# NUC1xx_registers register map
File version: 0.1
CPU: 
Registers are 32-bit, read-write, reset 0x0 unless marked. A register's access mark holds for its fields unless they carry their own. Offsets are from the block's base; [hi:lo] are bit positions; lines under a group give offsets from that group; {n}, {i} and the like mark numbered series; 'fields as' and 'values as' point back to an identical list; <NAME> marks a mode.

## PWMA — Registers group
Base 0x40040000
Same registers: PWMB 0x40140000
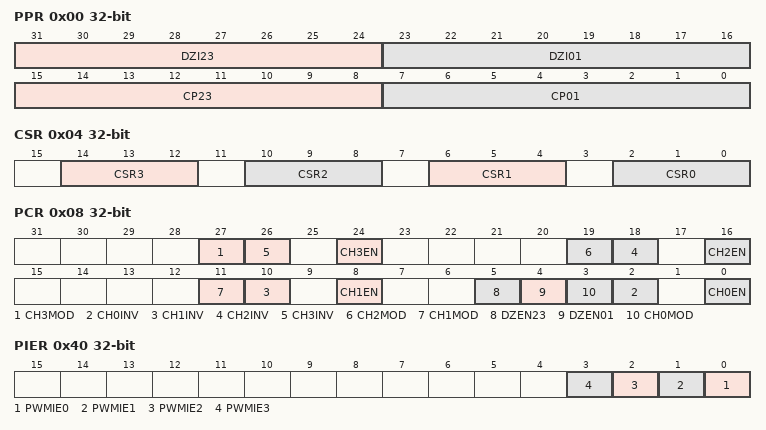
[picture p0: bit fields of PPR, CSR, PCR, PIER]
0x00 PPR — PWM Prescaler Register
  [31:24] DZI23 — Dead Zone Interval for Pair of Channel2 and Channel3 (PWM2 and PWM3 pair for PWM group A, PWM6 and PWM7 pair for PWM group B) These 8 bits determine dead zone length. The unit time of dead zone length is received from corresponding CSR bits.
  [23:16] DZI01 — Dead Zone Interval for Pair of Channel 0 and Channel 1 (PWM0 and PWM1 pair for PWM group A, PWM4 and PWM5 pair for PWM group B) These 8 bits determine dead zone length. The unit time of dead zone length is received from corresponding CSR bits.
  [15:8] CP23 — Clock prescaler 2 (PWM-timer2 & 3 for group A and PWM-timer 6 & 7 for group B) Clock input is divided by (CP23 + 1) before it is fed to the corresponding PWM-timer. If CP23=0, then the clock prescaler 2 output clock will be stopped. So corresponding PWM-timer will be stopped also.
  [7:0] CP01 — Clock prescaler 0 (PWM-timer 0 & 1 for group A and PWM-timer 4 & 5 for group B) Clock input is divided by (CP01 + 1) before it is fed to the corresponding PWM-timer If CP01=0, then the clock prescaler 0 output clock will be stopped. So corresponding PWM-timer will be stopped also.
0x04 CSR — PWM Clock Select Register
  [14:12] CSR3 — PWM Timer 3 Clock Source Selection (PWM timer 3 for group A and PWM timer 7 for group B) Select clock input for PWM timer. CSR3 [14:12] Input clock divided by 100 1 011 16 010 8 001 4 000 2
  [10:8] CSR2 — PWM Timer 2 Clock Source Selection (PWM timer 2 for group A and PWM timer 6 for group B) Select clock input for PWM timer. (Table is the same as CSR3)
  [6:4] CSR1 — PWM Timer 1 Clock Source Selection (PWM timer 1 for group A and PWM timer 5 for group B) Select clock input for PWM timer. (Table is the same as CSR3)
  [2:0] CSR0 — PWM Timer 0 Clock Source Selection (PWM timer 0 for group A and PWM timer 4 for group B) Select clock input for PWM timer. (Table is the same as CSR3)
0x08 PCR — PWM Control Register
  [27] CH3MOD — PWM-Timer 3 Auto-reload/One-Shot Mode (PWM timer 3 for group A and PWM timer 7 for group B) 1 = Auto-reload Mode 0 = One-Shot Mode Note: If there is a rising transition at this bit, it will cause CNR3 and CMR3 be clear.
  [8n+2] CH{n}INV (n=0..3) — PWM-Timer {n} Output Inverter Enable (PWM timer {n} for group A and PWM timer {n+4} for group B) 1 = Inverter enable 0 = Inverter disable
  [8n] CH{n}EN (n=0..3) — PWM-Timer {n} Enable (PWM timer {n} for group A and PWM timer {n+4} for group B) 1 = Enable corresponding PWM-Timer Start Run 0 = Stop corresponding PWM-Timer Running
  [19] CH2MOD — PWM-Timer 2 Auto-reload/One-Shot Mode (PWM timer 2 for group A and PWM timer 6 for group B) 1 = Auto-reload Mode 0 = One-Shot Mode Note: If there is a rising transition at this bit, it will cause CNR2 and CMR2 be clear.
  [11] CH1MOD — PWM-Timer 1 Auto-reload/One-Shot Mode (PWM timer 1 for group A and PWM timer 5 for group B) 1 = Auto-load Mode 0 = One-Shot Mode Note: If there is a rising transition at this bit, it will cause CNR1 and CMR1 be clear.
  [5] DZEN23 — Dead-Zone 2 Generator Enable (PWM2 and PWM3 pair for PWM group A, PWM6 and PWM7 pair for PWM group B) 1 = Enable 0 = Disable Note: When Dead-Zone Generator is enabled, the pair of PWM2 and PWM3 becomes a complementary pair for PWM group A and the pair of PWM6 and PWM7 becomes a complementary pair for PWM group B.
  [4] DZEN01 — Dead-Zone 0 Generator Enable (PWM0 and PWM1 pair for PWM group A, PWM4 and PWM5 pair for PWM group B) 1 = Enable 0 = Disable Note: When Dead-Zone Generator is enabled, the pair of PWM0 and PWM1 becomes a complementary pair for PWM group A and the pair of PWM4 and PWM5 becomes a complementary pair for PWM group B.
  [3] CH0MOD — PWM-Timer 0 Auto-reload/One-Shot Mode (PWM timer 0 for group A and PWM timer 4 for group B) 1 = Auto-reload Mode 0 = One-Shot Mode Note: If there is a rising transition at this bit, it will cause CNR0 and CMR0 be clear.
0x0C CNR0 — PWM Counter Register 0
  [15:0] CNR — PWM Counter/Timer Loaded Value CNR determines the PWM period. PWM frequency = PWM01_CLK/(prescale+1)*(clock divider)/(CNR+1). Duty ratio = (CMR+1)/(CNR+1). CMR >= CNR: PWM output is always high. CMR < CNR: PWM low width = (CNR-CMR) unit; PWM high width = (CMR+1) unit. CMR = 0: PWM low width = (CNR) unit; PWM high width = 1 unit (Unit : 1 PWM clock cycle) Note: Any write to CNR will take effect in next PWM cycle.
0x10 CMR0 — PWM Comparator Register 0
  [15:0] CMR — PWM Comparator Register CMR determines the PWM duty. PWM frequency = PWM01_CLK/(prescale+1)*(clock divider)/(CNR+1). Duty ratio = (CMR+1)/(CNR+1). CMR >= CNR: PWM output is always high. CMR < CNR: PWM low width = (CNR-CMR) unit; PWM high width = (CMR+1) unit. CMR = 0: PWM low width = (CNR) unit; PWM high width = 1 unit (Unit : 1 PWM clock cycle) Note: Any write to CMR will take effect in next PWM cycle.
{0x14+0xC*i} PDR{i} ro (i=0..3) — PWM Data Register {i}
  [15:0] PDR — PWM Data Register User can monitor PDR to know current value in 16-bit down counter.
0x18 CNR1 — PWM Counter Register 1
  fields as CNR0
0x1C CMR1 — PWM Comparator Register 1
  fields as CMR0
0x24 CNR2 — PWM Counter Register 2
  [15:0] CNR — PWM Counter/Timer Loaded Value CNR determines the PWM period. PWM frequency = PWM23_CLK/(prescale+1)*(clock divider)/(CNR+1). Duty ratio = (CMR+1)/(CNR+1). CMR >= CNR: PWM output is always high. CMR < CNR: PWM low width = (CNR-CMR) unit; PWM high width = (CMR+1) unit. CMR = 0: PWM low width = (CNR) unit; PWM high width = 1 unit (Unit : 1 PWM clock cycle) Note: Any write to CNR will take effect in next PWM cycle.
0x28 CMR2 — PWM Comparator Register 2
  [15:0] CMR — PWM Comparator Register CMR determines the PWM duty. PWM frequency = PWM23_CLK/(prescale+1)*(clock divider)/(CNR+1). Duty ratio = (CMR+1)/(CNR+1). CMR >= CNR: PWM output is always high. CMR < CNR: PWM low width = (CNR-CMR) unit; PWM high width = (CMR+1) unit. CMR = 0: PWM low width = (CNR) unit; PWM high width = 1 unit (Unit : 1 PWM clock cycle) Note: Any write to CMR will take effect in next PWM cycle.
0x30 CNR3 — PWM Counter Register 3
  fields as CNR2
0x34 CMR3 — PWM Comparator Register 3
  fields as CMR2
0x3C PBCR — New description for register
  [0] BCn — PWM Backward Compatible Register 0 = PWM register action is compatible with Medium Density 1 = PWM register action is not compatible with Medium Density Please reference CCR0/CCR2 register bit 6, 7, 22, 23 description
0x40 PIER — PWM Interrupt Enable Register
  [n] PWMIE{n} (n=0..3) — PWM Channel {n} Interrupt Enable 1 = Enable 0 = Disable
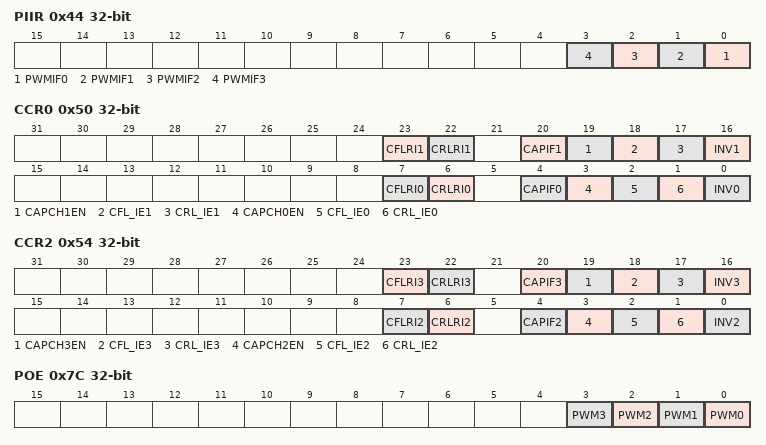
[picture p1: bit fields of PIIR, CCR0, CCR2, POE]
0x44 PIIR — PWM Interrupt Indication Register
  [n] PWMIF{n} write-1-clears (n=0..3) — PWM Channel {n} Interrupt Status Flag is set by hardware when PWM{n} down counter reaches zero, software can write 1 to clear this bit to zero.
0x50 CCR0 — Capture Control Register 0
  [23] CFLRI1 — CFLR1 Latched Indicator Bit When PWM group input channel 1 has a falling transition, CFLR1 was latched with the value of PWM down-counter and this bit is set by hardware. In Medium Density, software can write 0 to clear this bit to zero. In Low Density, software can write 0 to clear this bit to zero if BCn bit is 0, and can Write 1 to clear this bit to zero if BCn bit is 1.
  [22] CRLRI1 — CRLR1 Latched Indicator Bit When PWM group input channel 1 has a rising transition, CRLR1 was latched with the value of PWM down-counter and this bit is set by hardware. In Medium Density, software can write 0 to clear this bit to zero. In Low Density, software can write 0 to clear this bit to zero if BCn bit is 0, and can Write 1 to clear this bit to zero if BCn bit is 1.
  [20] CAPIF1 write-1-clears — Channel 1 Capture Interrupt Indication Flag If PWM group channel 1 rising latch interrupt is enabled (CRL_IE1=1), a rising transition occurs at PWM group channel 1 will result in CAPIF1 to high; Similarly, a falling transition will cause CAPIF1 to be set high if PWM group channel 1 falling latch interrupt is enabled (CFL_IE1=1). Write 1 to clear this bit to zero
  [19] CAPCH1EN — Channel 1 Capture Function Enable 1 = Enable capture function on PWM group channel 1. 0 = Disable capture function on PWM group channel 1. When Enable, Capture latched the PMW-counter and saved to CRLR (Rising latch) and CFLR (Falling latch). When Disable, Capture does not update CRLR and CFLR, and disable PWM group channel 1 Interrupt.
  [18] CFL_IE1 — Channel 1 Falling Latch Interrupt Enable 1 = Enable falling latch interrupt 0 = Disable falling latch interrupt When Enable, if Capture detects PWM group channel 1 has falling transition, Capture issues an Interrupt.
  [17] CRL_IE1 — Channel 1 Rising Latch Interrupt Enable 1 = Enable rising latch interrupt 0 = Disable rising latch interrupt When Enable, if Capture detects PWM group channel 1 has rising transition, Capture issues an Interrupt.
  [16] INV1 — Channel 1 Inverter Enable 1 = Inverter enable. Reverse the input signal from GPIO before fed to Capture timer 0 = Inverter disable
  [7] CFLRI0 — CFLR0 Latched Indicator Bit When PWM group input channel 0 has a falling transition, CFLR0 was latched with the value of PWM down-counter and this bit is set by hardware. In Medium Density, software can write 0 to clear this bit to zero. In Low Density, software can write 0 to clear this bit to zero if BCn bit is 0, and can Write 1 to clear this bit to zero if BCn bit is 1.
  [6] CRLRI0 — CRLR0 Latched Indicator Bit When PWM group input channel 0 has a rising transition, CRLR0 was latched with the value of PWM down-counter and this bit is set by hardware. In Medium Density, software can write 0 to clear this bit to zero. In Low Density, software can write 0 to clear this bit to zero if BCn bit is 0, and can Write 1 to clear this bit to zero if BCn bit is 1.
  [4] CAPIF0 write-1-clears — Channel 0 Capture Interrupt Indication Flag If PWM group channel 0 rising latch interrupt is enabled (CRL_IE0=1), a rising transition occurs at PWM group channel 0 will result in CAPIF0 to high; Similarly, a falling transition will cause CAPIF0 to be set high if PWM group channel 0 falling latch interrupt is enabled (CFL_IE0=1). Write 1 to clear this bit to zero
  [3] CAPCH0EN — Channel 0 Capture Function Enable 1 = Enable capture function on PWM group channel 0. 0 = Disable capture function on PWM group channel 0. When Enable, Capture latched the PWM-counter value and saved to CRLR (Rising latch) and CFLR (Falling latch). When Disable, Capture does not update CRLR and CFLR, and disable PWM group channel 0 Interrupt.
  [2] CFL_IE0 — Channel 0 Falling Latch Interrupt Enable 1 = Enable falling latch interrupt 0 = Disable falling latch interrupt When Enable, if Capture detects PWM group channel 0 has falling transition, Capture issues an Interrupt.
  [1] CRL_IE0 — Channel 0 Rising Latch Interrupt Enable 1 = Enable rising latch interrupt 0 = Disable rising latch interrupt When Enable, if Capture detects PWM group channel 0 has rising transition, Capture issues an Interrupt.
  [0] INV0 — Channel 0 Inverter Enable 1 = Inverter enable. Reverse the input signal from GPIO before fed to Capture timer 0 = Inverter disable
0x54 CCR2 — Capture Control Register 2
  [23] CFLRI3 — CFLR3 Latched Indicator Bit When PWM group input channel 3 has a falling transition, CFLR3 was latched with the value of PWM down-counter and this bit is set by hardware. In Medium Density, software can write 0 to clear this bit to zero. In Low Density, software can write 0 to clear this bit to zero if BCn bit is 0, and can Write 1 to clear this bit to zero if BCn bit is 1.
  [22] CRLRI3 — CRLR3 Latched Indicator Bit When PWM group input channel 3 has a rising transition, CRLR3 was latched with the value of PWM down-counter and this bit is set by hardware. In Medium Density, software can write 0 to clear this bit to zero. In Low Density, software can write 0 to clear this bit to zero if BCn bit is 0, and can Write 1 to clear this bit to zero if BCn bit is 1.
  [20] CAPIF3 write-1-clears — Channel 3 Capture Interrupt Indication Flag If PWM group channel 3 rising latch interrupt is enabled (CRL_IE3=1), a rising transition occurs at PWM group channel 3 will result in CAPIF3 to high; Similarly, a falling transition will cause CAPIF3 to be set high if PWM group channel 3 falling latch interrupt is enabled (CFL_IE3=1). Write 1 to clear this bit to zero
  [19] CAPCH3EN — Channel 3 Capture Function Enable 1 = Enable capture function on PWM group channel 3. 0 = Disable capture function on PWM group channel 3. When Enable, Capture latched the PMW-counter and saved to CRLR (Rising latch) and CFLR (Falling latch). When Disable, Capture does not update CRLR and CFLR, and disable PWM group channel 3 Interrupt.
  [18] CFL_IE3 — Channel 3 Falling Latch Interrupt Enable 1 = Enable falling latch interrupt 0 = Disable falling latch interrupt When Enable, if Capture detects PWM group channel 3 has falling transition, Capture issues an Interrupt.
  [17] CRL_IE3 — Channel 3 Rising Latch Interrupt Enable 1 = Enable rising latch interrupt 0 = Disable rising latch interrupt When Enable, if Capture detects PWM group channel 3 has rising transition, Capture issues an Interrupt.
  [16] INV3 — Channel 3 Inverter Enable 1 = Inverter enable. Reverse the input signal from GPIO before fed to Capture timer 0 = Inverter disable
  [7] CFLRI2 — CFLR2 Latched Indicator Bit When PWM group input channel 2 has a falling transition, CFLR2 was latched with the value of PWM down-counter and this bit is set by hardware. In Medium Density, software can write 0 to clear this bit to zero. In Low Density, software can write 0 to clear this bit to zero if BCn bit is 0, and can Write 1 to clear this bit to zero if BCn bit is 1.
  [6] CRLRI2 — CRLR2 Latched Indicator Bit When PWM group input channel 2 has a rising transition, CRLR2 was latched with the value of PWM down-counter and this bit is set by hardware. In Medium Density, software can write 0 to clear this bit to zero. In Low Density, software can write 0 to clear this bit to zero if BCn bit is 0, and can Write 1 to clear this bit to zero if BCn bit is 1.
  [4] CAPIF2 write-1-clears — Channel 2 Capture Interrupt Indication Flag If PWM group channel 2 rising latch interrupt is enabled (CRL_IE2=1), a rising transition occurs at PWM group channel 2 will result in CAPIF2 to high; Similarly, a falling transition will cause CAPIF2 to be set high if PWM group channel 2 falling latch interrupt is enabled (CFL_IE2=1). Write 1 to clear this bit to zero
  [3] CAPCH2EN — Channel 2 Capture Function Enable 1 = Enable capture function on PWM group channel 2. 0 = Disable capture function on PWM group channel 2. When Enable, Capture latched the PWM-counter value and saved to CRLR (Rising latch) and CFLR (Falling latch). When Disable, Capture does not update CRLR and CFLR, and disable PWM group channel 2 Interrupt.
  [2] CFL_IE2 — Channel 2 Falling Latch Interrupt Enable 1 = Enable falling latch interrupt 0 = Disable falling latch interrupt When Enable, if Capture detects PWM group channel 2 has falling transition, Capture issues an Interrupt.
  [1] CRL_IE2 — Channel 2 Rising Latch Interrupt Enable 1 = Enable rising latch interrupt 0 = Disable rising latch interrupt When Enable, if Capture detects PWM group channel 2 has rising transition, Capture issues an Interrupt.
  [0] INV2 — Channel 2 Inverter Enable 1 = Inverter enable. Reverse the input signal from GPIO before fed to Capture timer 0 = Inverter disable
0x58 CRLR0 ro — Capture Rising Latch Register (Channel 0)
  [15:0] CRLR — Capture Rising Latch Register Latch the PWM counter when Channel 0 has rising transition.
0x5C CFLR0 ro — Capture Falling Latch Register (Channel 0)
  [15:0] CFLR — Capture Falling Latch Register Latch the PWM counter when Channel 0 has Falling transition.
0x60 CRLR1 ro — Capture Rising Latch Register (Channel 1)
  [15:0] CRLR — Capture Rising Latch Register Latch the PWM counter when Channel 1 has rising transition.
0x64 CFLR1 ro — Capture Falling Latch Register (Channel 1)
  [15:0] CFLR — Capture Falling Latch Register Latch the PWM counter when Channel 1 has Falling transition.
0x68 CRLR2 ro — Capture Rising Latch Register (channel 2)
  [15:0] CRLR — Capture Rising Latch Register Latch the PWM counter when Channel 2 has rising transition.
0x6C CFLR2 ro — Capture Falling Latch Register (channel 2)
  [15:0] CFLR — Capture Falling Latch Register Latch the PWM counter when Channel 2 has Falling transition.
0x70 CRLR3 ro — Capture Rising Latch Register (channel 3)
  [15:0] CRLR — Capture Rising Latch Register Latch the PWM counter when Channel 3 has rising transition.
0x74 CFLR3 ro — Capture Falling Latch Register (channel 3)
  [15:0] CFLR — Capture Falling Latch Register Latch the PWM counter when Channel 3 has Falling transition.
0x78 CAPENR — Capture Input Enable Register
  [3:0] CAPENR — Capture Input Enable Register There are four capture inputs from pad. Bit0~Bit3 are used to control each inputs enable or disable. 0 = Disable (PWMx multi-function pin input does not affect input capture function) 1 = Enable (PWMx multi-function pin input will affect its input capture function.) CAPENR Bit 3210 for PWM group A Bit xxx1 Capture channel 0 is from pin PA.12 Bit xx1x Capture channel 1 is from pin PA.13 Bit x1xx Capture channel 2 is from pin PA.14 Bit 1xxx Capture channel 3 is from pin PA.15 Bit 3210 for PWM group B Bit xxx1 Capture channel 0 is from pin PE.11 Bit xx1x Capture channel 1 is from pin PE.5 Bit x1xx Capture channel 2 is from pin PE.0 Bit 1xxx Capture channel 3 is from pin PE.1
0x7C POE — PWM Output Enable Register
  [n] PWM{n} (n=0..3) — PWM Channel {n} Output Enable Register 1 = Enable PWM channel {n} output to pin 0 = Disable PWM channel {n} output to pin Note: The corresponding GPIO pin also must be switched to PWM function.
